VERSION ""

NS_ :

BS_:

BU_:

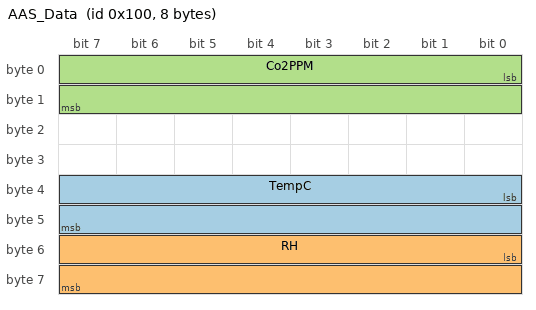
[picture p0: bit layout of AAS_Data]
BO_ 256 AAS_Data: 8 Vector__XXX
 SG_ TempC : 32|16@1- (0.1,0) [0|0] "" Vector__XXX
 SG_ RH : 48|16@1+ (0.002,0) [0|0] "" Vector__XXX
 SG_ Co2PPM : 0|16@1- (1,0) [0|0] "" Vector__XXX

BA_DEF_  "BusType" STRING ;
BA_DEF_DEF_  "BusType" "CAN";
